AUTOSAR XML (schema 00048)
package /ComponentTypes
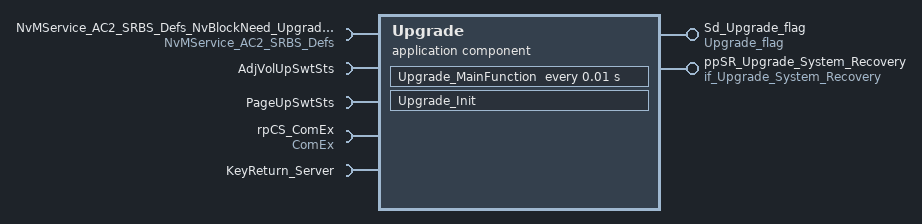
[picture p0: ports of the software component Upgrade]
  application sw component type Upgrade
    provide port Sd_Upgrade_flag: nonqueued-sender-com-spec{data-element=Element, init-value=0}, provided-interface=Upgrade_flag
    require port NvMService_AC2_SRBS_Defs_NvBlockNeed_UpgradeResetFlag: required-com-specs=[WriteBlock, SetRamBlockStatus, RestoreBlockDefaults, ReadBlock, GetErrorStatus], required-interface=NvMService_AC2_SRBS_Defs
    provide port ppSR_Upgrade_System_Recovery: nonqueued-sender-com-spec{data-element=System_Recovery, init-value=0}, provided-interface=if_Upgrade_System_Recovery
    4 x require port:
      AdjVolUpSwtSts: nonqueued-receiver-com-spec{data-element=AdjVolUpSwtSts, filter=data-filter-type=ALWAYS, init-value=0}, required-interface=AdjVolUpSwtSts
      PageUpSwtSts: nonqueued-receiver-com-spec{data-element=PageUpSwtSts, filter=data-filter-type=ALWAYS, init-value=0}, required-interface=PageUpSwtSts
      rpCS_ComEx: required-com-specs=[SendSignal, ReceiveSignal, GetRxE2EStatus], required-interface=ComEx
      KeyReturn_Server: required-com-specs=[disanle, enable, register, remove, State], required-interface=KeyReturn_Server
    behavior Upgrade_InternalBehavior
      ar-typed-per-instance-memorys:
        data NvBlockNeed_UpgradeResetFlag_MirrorBlock: sw-calibration-access=READ-ONLY, type=uint32
      init event Upgrade_InitEvent: start-on-event=Upgrade_Init
      timing event TMT_Upgrade_MainFunction: start-on-event=Upgrade_MainFunction, period=0.01
      runnable Upgrade_Init
        data-send-points:
          access SEND_ppSR_Upgrade_System_Recovery_System_Recovery: accessed-variable=ppSR_Upgrade_System_Recovery.System_Recovery
        5 x sync call:
          SC_KeyReturn_Server_State: operation=KeyReturn_Server.State
          SC_KeyReturn_Server_disanle: operation=KeyReturn_Server.disanle
          SC_KeyReturn_Server_enable: operation=KeyReturn_Server.enable
          SC_KeyReturn_Server_register: operation=KeyReturn_Server.register
          SC_KeyReturn_Server_remove: operation=KeyReturn_Server.remove
      runnable Upgrade_MainFunction
        data-receive-point-by-arguments:
          access REC_AdjVolUpSwtSts_AdjVolUpSwtSts: accessed-variable=AdjVolUpSwtSts.AdjVolUpSwtSts
          access REC_PageUpSwtSts_PageUpSwtSts: accessed-variable=PageUpSwtSts.PageUpSwtSts
        data-send-points:
          access SEND_Sd_Upgrade_flag_Element: accessed-variable=Sd_Upgrade_flag.Element
          access SEND_ppSR_Upgrade_System_Recovery_System_Recovery: accessed-variable=ppSR_Upgrade_System_Recovery.System_Recovery
        13 x sync call:
          SC_NvMService_AC2_SRBS_Defs_NvBlockNeed_UpgradeResetFlag_GetErrorStatus: operation=NvMService_AC2_SRBS_Defs_NvBlockNeed_UpgradeResetFlag.GetErrorStatus
          SC_NvMService_AC2_SRBS_Defs_NvBlockNeed_UpgradeResetFlag_ReadBlock: operation=NvMService_AC2_SRBS_Defs_NvBlockNeed_UpgradeResetFlag.ReadBlock
          SC_NvMService_AC2_SRBS_Defs_NvBlockNeed_UpgradeResetFlag_RestoreBlockDefaults: operation=NvMService_AC2_SRBS_Defs_NvBlockNeed_UpgradeResetFlag.RestoreBlockDefaults
          SC_NvMService_AC2_SRBS_Defs_NvBlockNeed_UpgradeResetFlag_SetRamBlockStatus: operation=NvMService_AC2_SRBS_Defs_NvBlockNeed_UpgradeResetFlag.SetRamBlockStatus
          SC_NvMService_AC2_SRBS_Defs_NvBlockNeed_UpgradeResetFlag_WriteBlock: operation=NvMService_AC2_SRBS_Defs_NvBlockNeed_UpgradeResetFlag.WriteBlock
          SC_rpCS_ComEx_GetRxE2EStatus: operation=rpCS_ComEx.GetRxE2EStatus
          SC_rpCS_ComEx_ReceiveSignal: operation=rpCS_ComEx.ReceiveSignal
          SC_rpCS_ComEx_SendSignal: operation=rpCS_ComEx.SendSignal
          SC_KeyReturn_Server_State: operation=KeyReturn_Server.State
          SC_KeyReturn_Server_disanle: operation=KeyReturn_Server.disanle
          SC_KeyReturn_Server_enable: operation=KeyReturn_Server.enable
          SC_KeyReturn_Server_register: operation=KeyReturn_Server.register
          SC_KeyReturn_Server_remove: operation=KeyReturn_Server.remove
      swc service dependency NvBlockNeed_UpgradeResetFlag: assigned-ports=role-based-port-assignment={port-prototype=NvMService_AC2_SRBS_Defs_NvBlockNeed_UpgradeResetFlag, role=NvMService_AC2_SRBS_Defs}
        assigned-datas:
          role=ramBlock, used-data-element=NvBlockNeed_UpgradeResetFlag_MirrorBlock
          role=defaultValue, used-parameter-element=NvBlockNeed_UpgradeResetFlag_DefaultValue
        service-needs:
          nv block needs NvBlockNeed_UpgradeResetFlag: n-data-sets=0, ram-block-status-control=API, reliability=NO-PROTECTION, restore-at-start=false, store-at-shutdown=false
      shared-parameters:
        parameter data prototype NvBlockNeed_UpgradeFlag_DefaultValue: sw-calibration-access=READ-WRITE, type=uint32, init-value=0
        parameter data prototype NvBlockNeed_Upgrade_Flag_DefaultValue: sw-calibration-access=READ-WRITE, type=uint32, init-value=0
        parameter data prototype NvBlockNeed_UpgradeResetFlag_DefaultValue: sw-calibration-access=READ-WRITE, type=uint32, init-value=0
  swc implementation Upgrade_Implementation: behavior=Upgrade_InternalBehavior
